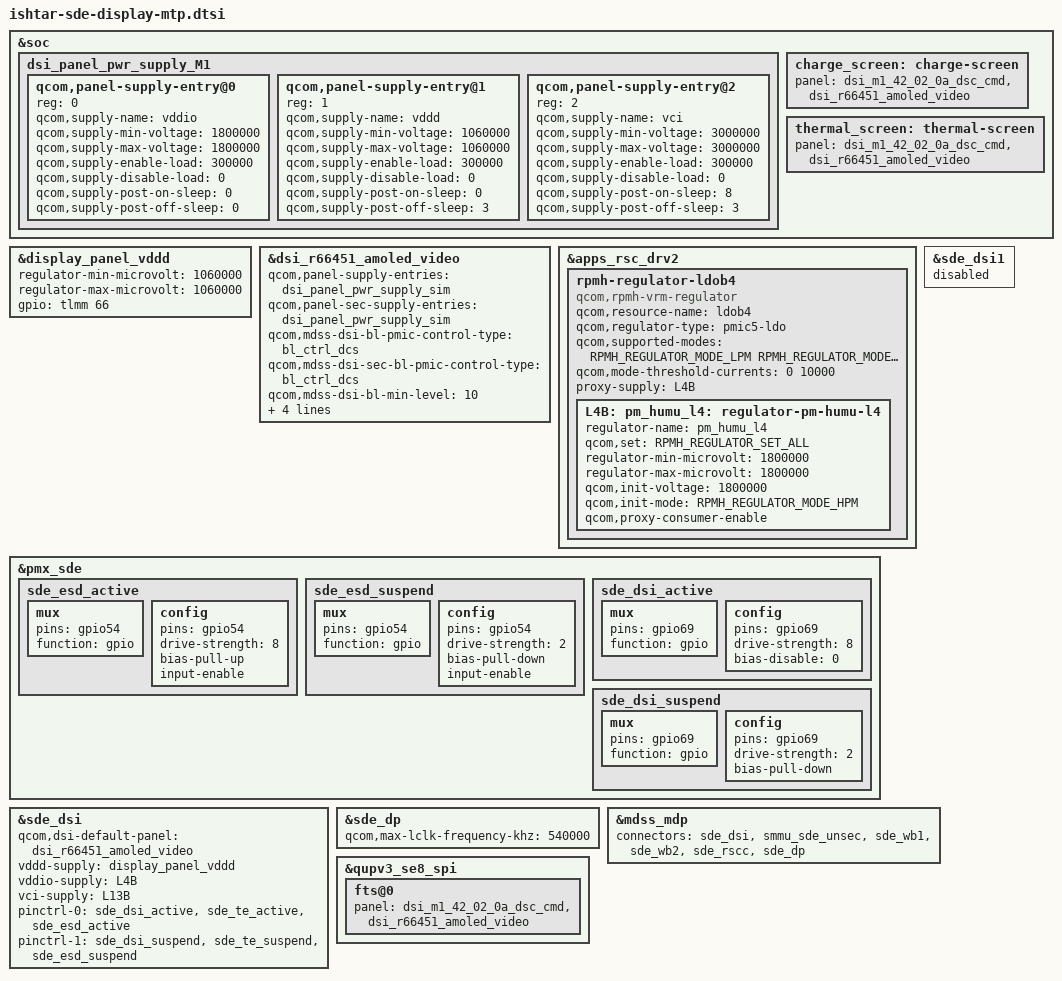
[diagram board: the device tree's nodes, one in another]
#include "kalama-sde-display.dtsi"
#include "dsi-panel-m1-42-02-0a-dsc-cmd.dtsi"

&soc {
	dsi_panel_pwr_supply_M1: dsi_panel_pwr_supply_M1 {
		qcom,panel-supply-entry@0 {
			reg = <0>;
			qcom,supply-name = "vddio";
			qcom,supply-min-voltage = <1800000>;
			qcom,supply-max-voltage = <1800000>;
			qcom,supply-enable-load = <300000>;
			qcom,supply-disable-load = <0>;
			qcom,supply-post-on-sleep = <0>;
			qcom,supply-post-off-sleep = <0>;
		};
		qcom,panel-supply-entry@1 {
			reg = <1>;
			qcom,supply-name = "vddd";
			qcom,supply-min-voltage = <1060000>;
			qcom,supply-max-voltage = <1060000>;
			qcom,supply-enable-load = <300000>;
			qcom,supply-disable-load = <0>;
			qcom,supply-post-on-sleep = <0>;
			qcom,supply-post-off-sleep = <3>;
		};
		qcom,panel-supply-entry@2 {
			reg = <2>;
			qcom,supply-name = "vci";
			qcom,supply-min-voltage = <3000000>;
			qcom,supply-max-voltage = <3000000>;
			qcom,supply-enable-load = <300000>;
			qcom,supply-disable-load = <0>;
			qcom,supply-post-on-sleep = <8>;
			qcom,supply-post-off-sleep = <3>;
		};
	};
};

&display_panel_vddd {
	regulator-min-microvolt = <1060000>;
	regulator-max-microvolt = <1060000>;
	gpio = <&tlmm 66 0>;
};

&dsi_r66451_amoled_video {
	qcom,panel-supply-entries = <&dsi_panel_pwr_supply_sim>;
	qcom,panel-sec-supply-entries = <&dsi_panel_pwr_supply_sim>;
	qcom,mdss-dsi-bl-pmic-control-type = "bl_ctrl_dcs";
	qcom,mdss-dsi-sec-bl-pmic-control-type = "bl_ctrl_dcs";
	qcom,mdss-dsi-bl-min-level = <10>;
	qcom,mdss-dsi-bl-max-level = <4095>;
	qcom,mdss-brightness-max-level = <8191>;
	qcom,mdss-dsi-bl-inverted-dbv;
	qcom,platform-reset-gpio = <&tlmm 69 0>;
	/delete-property/qcom,esd-check-enabled;
};

&apps_rsc_drv2 {
	rpmh-regulator-ldob4 {
		compatible = "qcom,rpmh-vrm-regulator";
		qcom,resource-name = "ldob4";
		qcom,regulator-type = "pmic5-ldo";
		qcom,supported-modes =
			<RPMH_REGULATOR_MODE_LPM
			 RPMH_REGULATOR_MODE_HPM>;
		qcom,mode-threshold-currents = <0 10000>;
		proxy-supply = <&L4B>;

		L4B: pm_humu_l4: regulator-pm-humu-l4 {
			regulator-name = "pm_humu_l4";
			qcom,set = <RPMH_REGULATOR_SET_ALL>;
			regulator-min-microvolt = <1800000>;
			regulator-max-microvolt = <1800000>;
			qcom,init-voltage = <1800000>;
			qcom,init-mode = <RPMH_REGULATOR_MODE_HPM>;
			qcom,proxy-consumer-enable;
		};
	};
};

&pmx_sde {
	sde_esd_active: sde_esd_active {
		mux {
			pins = "gpio54";
			function = "gpio";
		};

		config {
			pins = "gpio54";
			drive-strength = <8>;   /* 8 mA */
			bias-pull-up;   /* PULL UP */
			input-enable;
		};
	};

	sde_esd_suspend: sde_esd_suspend {
		mux {
			pins = "gpio54";
			function = "gpio";
		};

		config {
			pins = "gpio54";
			drive-strength = <2>;   /* 2 mA */
			bias-pull-down;         /* PULL DOWN */
			input-enable;
		};
	};

	sde_dsi_active: sde_dsi_active {
		mux {
			pins = "gpio69";
			function = "gpio";
		};

		config {
			pins = "gpio69";
			drive-strength = <8>;   /* 8 mA */
			bias-disable = <0>;   /* no pull */
		};
	};

	sde_dsi_suspend: sde_dsi_suspend {
		mux {
			pins = "gpio69";
			function = "gpio";
		};

		config {
			pins = "gpio69";
			drive-strength = <2>;   /* 2 mA */
			bias-pull-down;         /* PULL DOWN */
		};
	};
};

&sde_dsi {
	qcom,dsi-default-panel = <&dsi_r66451_amoled_video>;
	vddd-supply = <&display_panel_vddd>;
	vddio-supply = <&L4B>;
	vci-supply = <&L13B>;
	pinctrl-0 = <&sde_dsi_active &sde_te_active &sde_esd_active>;
	pinctrl-1 = <&sde_dsi_suspend &sde_te_suspend &sde_esd_suspend>;
};

&sde_dsi1 {
	status = "disabled";
};

&sde_dp {
	qcom,max-lclk-frequency-khz = <540000>;
	status = "ok";
};

&mdss_mdp {
	connectors = <&sde_dsi &smmu_sde_unsec &sde_wb1 &sde_wb2 &sde_rscc &sde_dp>;
};

&qupv3_se8_spi {
	fts@0 {
		panel = <&dsi_m1_42_02_0a_dsc_cmd
			&dsi_r66451_amoled_video>;
	};
};

&soc {
	charge_screen: charge-screen {
		panel  = <&dsi_m1_42_02_0a_dsc_cmd
			&dsi_r66451_amoled_video>;
	};
};

&soc {
	thermal_screen: thermal-screen {
		panel = <&dsi_m1_42_02_0a_dsc_cmd
			&dsi_r66451_amoled_video>;
	};
};
